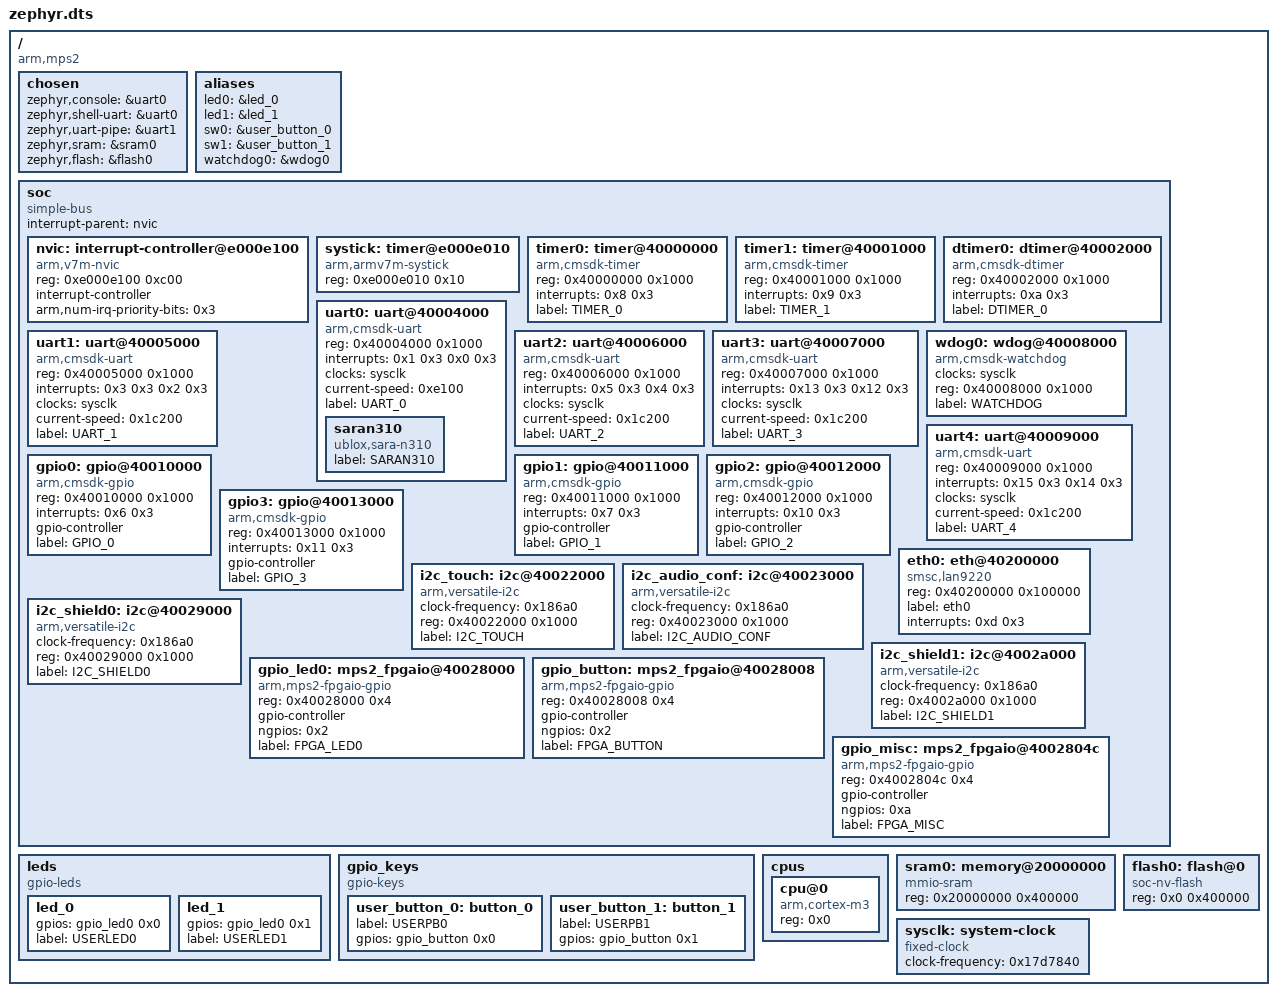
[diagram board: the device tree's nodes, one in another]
/dts-v1/;

/ {
	#address-cells = < 0x1 >;
	#size-cells = < 0x1 >;
	compatible = "arm,mps2";
	chosen {
		zephyr,console = &uart0;
		zephyr,shell-uart = &uart0;
		zephyr,uart-pipe = &uart1;
		zephyr,sram = &sram0;
		zephyr,flash = &flash0;
	};
	aliases {
		led0 = &led_0;
		led1 = &led_1;
		sw0 = &user_button_0;
		sw1 = &user_button_1;
		watchdog0 = &wdog0;
	};
	soc {
		#address-cells = < 0x1 >;
		#size-cells = < 0x1 >;
		compatible = "simple-bus";
		interrupt-parent = < &nvic >;
		ranges;
		nvic: interrupt-controller@e000e100 {
			compatible = "arm,v7m-nvic";
			reg = < 0xe000e100 0xc00 >;
			interrupt-controller;
			#interrupt-cells = < 0x2 >;
			arm,num-irq-priority-bits = < 0x3 >;
			phandle = < 0x1 >;
		};
		systick: timer@e000e010 {
			compatible = "arm,armv7m-systick";
			reg = < 0xe000e010 0x10 >;
		};
		timer0: timer@40000000 {
			compatible = "arm,cmsdk-timer";
			reg = < 0x40000000 0x1000 >;
			interrupts = < 0x8 0x3 >;
			label = "TIMER_0";
		};
		timer1: timer@40001000 {
			compatible = "arm,cmsdk-timer";
			reg = < 0x40001000 0x1000 >;
			interrupts = < 0x9 0x3 >;
			label = "TIMER_1";
		};
		dtimer0: dtimer@40002000 {
			compatible = "arm,cmsdk-dtimer";
			reg = < 0x40002000 0x1000 >;
			interrupts = < 0xa 0x3 >;
			label = "DTIMER_0";
		};
		uart0: uart@40004000 {
			compatible = "arm,cmsdk-uart";
			reg = < 0x40004000 0x1000 >;
			interrupts = < 0x1 0x3 0x0 0x3 >;
			interrupt-names = "tx", "rx";
			clocks = < &sysclk >;
			current-speed = < 0xe100 >;
			label = "UART_0";
			status = "okay";
			saran310 {
				compatible = "ublox,sara-n310";
				label = "SARAN310";
			};
		};
		uart1: uart@40005000 {
			compatible = "arm,cmsdk-uart";
			reg = < 0x40005000 0x1000 >;
			interrupts = < 0x3 0x3 0x2 0x3 >;
			interrupt-names = "tx", "rx";
			clocks = < &sysclk >;
			current-speed = < 0x1c200 >;
			label = "UART_1";
		};
		uart2: uart@40006000 {
			compatible = "arm,cmsdk-uart";
			reg = < 0x40006000 0x1000 >;
			interrupts = < 0x5 0x3 0x4 0x3 >;
			interrupt-names = "tx", "rx";
			clocks = < &sysclk >;
			current-speed = < 0x1c200 >;
			label = "UART_2";
		};
		uart3: uart@40007000 {
			compatible = "arm,cmsdk-uart";
			reg = < 0x40007000 0x1000 >;
			interrupts = < 0x13 0x3 0x12 0x3 >;
			interrupt-names = "tx", "rx";
			clocks = < &sysclk >;
			current-speed = < 0x1c200 >;
			label = "UART_3";
		};
		wdog0: wdog@40008000 {
			compatible = "arm,cmsdk-watchdog";
			clocks = < &sysclk >;
			reg = < 0x40008000 0x1000 >;
			label = "WATCHDOG";
		};
		uart4: uart@40009000 {
			compatible = "arm,cmsdk-uart";
			reg = < 0x40009000 0x1000 >;
			interrupts = < 0x15 0x3 0x14 0x3 >;
			interrupt-names = "tx", "rx";
			clocks = < &sysclk >;
			current-speed = < 0x1c200 >;
			label = "UART_4";
		};
		gpio0: gpio@40010000 {
			compatible = "arm,cmsdk-gpio";
			reg = < 0x40010000 0x1000 >;
			interrupts = < 0x6 0x3 >;
			gpio-controller;
			#gpio-cells = < 0x2 >;
			label = "GPIO_0";
		};
		gpio1: gpio@40011000 {
			compatible = "arm,cmsdk-gpio";
			reg = < 0x40011000 0x1000 >;
			interrupts = < 0x7 0x3 >;
			gpio-controller;
			#gpio-cells = < 0x2 >;
			label = "GPIO_1";
		};
		gpio2: gpio@40012000 {
			compatible = "arm,cmsdk-gpio";
			reg = < 0x40012000 0x1000 >;
			interrupts = < 0x10 0x3 >;
			gpio-controller;
			#gpio-cells = < 0x2 >;
			label = "GPIO_2";
		};
		gpio3: gpio@40013000 {
			compatible = "arm,cmsdk-gpio";
			reg = < 0x40013000 0x1000 >;
			interrupts = < 0x11 0x3 >;
			gpio-controller;
			#gpio-cells = < 0x2 >;
			label = "GPIO_3";
		};
		eth0: eth@40200000 {
			compatible = "smsc,lan9220";
			reg = < 0x40200000 0x100000 >;
			label = "eth0";
			interrupts = < 0xd 0x3 >;
		};
		i2c_touch: i2c@40022000 {
			compatible = "arm,versatile-i2c";
			clock-frequency = < 0x186a0 >;
			#address-cells = < 0x1 >;
			#size-cells = < 0x0 >;
			reg = < 0x40022000 0x1000 >;
			label = "I2C_TOUCH";
		};
		i2c_audio_conf: i2c@40023000 {
			compatible = "arm,versatile-i2c";
			clock-frequency = < 0x186a0 >;
			#address-cells = < 0x1 >;
			#size-cells = < 0x0 >;
			reg = < 0x40023000 0x1000 >;
			label = "I2C_AUDIO_CONF";
		};
		i2c_shield0: i2c@40029000 {
			compatible = "arm,versatile-i2c";
			clock-frequency = < 0x186a0 >;
			#address-cells = < 0x1 >;
			#size-cells = < 0x0 >;
			reg = < 0x40029000 0x1000 >;
			label = "I2C_SHIELD0";
		};
		i2c_shield1: i2c@4002a000 {
			compatible = "arm,versatile-i2c";
			clock-frequency = < 0x186a0 >;
			#address-cells = < 0x1 >;
			#size-cells = < 0x0 >;
			reg = < 0x4002a000 0x1000 >;
			label = "I2C_SHIELD1";
		};
		gpio_led0: mps2_fpgaio@40028000 {
			compatible = "arm,mps2-fpgaio-gpio";
			reg = < 0x40028000 0x4 >;
			gpio-controller;
			#gpio-cells = < 0x1 >;
			ngpios = < 0x2 >;
			label = "FPGA_LED0";
			phandle = < 0x3 >;
		};
		gpio_button: mps2_fpgaio@40028008 {
			compatible = "arm,mps2-fpgaio-gpio";
			reg = < 0x40028008 0x4 >;
			gpio-controller;
			#gpio-cells = < 0x1 >;
			ngpios = < 0x2 >;
			label = "FPGA_BUTTON";
			phandle = < 0x4 >;
		};
		gpio_misc: mps2_fpgaio@4002804c {
			compatible = "arm,mps2-fpgaio-gpio";
			reg = < 0x4002804c 0x4 >;
			gpio-controller;
			#gpio-cells = < 0x1 >;
			ngpios = < 0xa >;
			label = "FPGA_MISC";
		};
	};
	leds {
		compatible = "gpio-leds";
		led_0: led_0 {
			gpios = < &gpio_led0 0x0 >;
			label = "USERLED0";
		};
		led_1: led_1 {
			gpios = < &gpio_led0 0x1 >;
			label = "USERLED1";
		};
	};
	gpio_keys {
		compatible = "gpio-keys";
		user_button_0: button_0 {
			label = "USERPB0";
			gpios = < &gpio_button 0x0 >;
		};
		user_button_1: button_1 {
			label = "USERPB1";
			gpios = < &gpio_button 0x1 >;
		};
	};
	cpus {
		#address-cells = < 0x1 >;
		#size-cells = < 0x0 >;
		cpu@0 {
			compatible = "arm,cortex-m3";
			reg = < 0x0 >;
		};
	};
	sram0: memory@20000000 {
		compatible = "mmio-sram";
		reg = < 0x20000000 0x400000 >;
	};
	flash0: flash@0 {
		compatible = "soc-nv-flash";
		reg = < 0x0 0x400000 >;
	};
	sysclk: system-clock {
		compatible = "fixed-clock";
		clock-frequency = < 0x17d7840 >;
		#clock-cells = < 0x0 >;
		phandle = < 0x2 >;
	};
};
